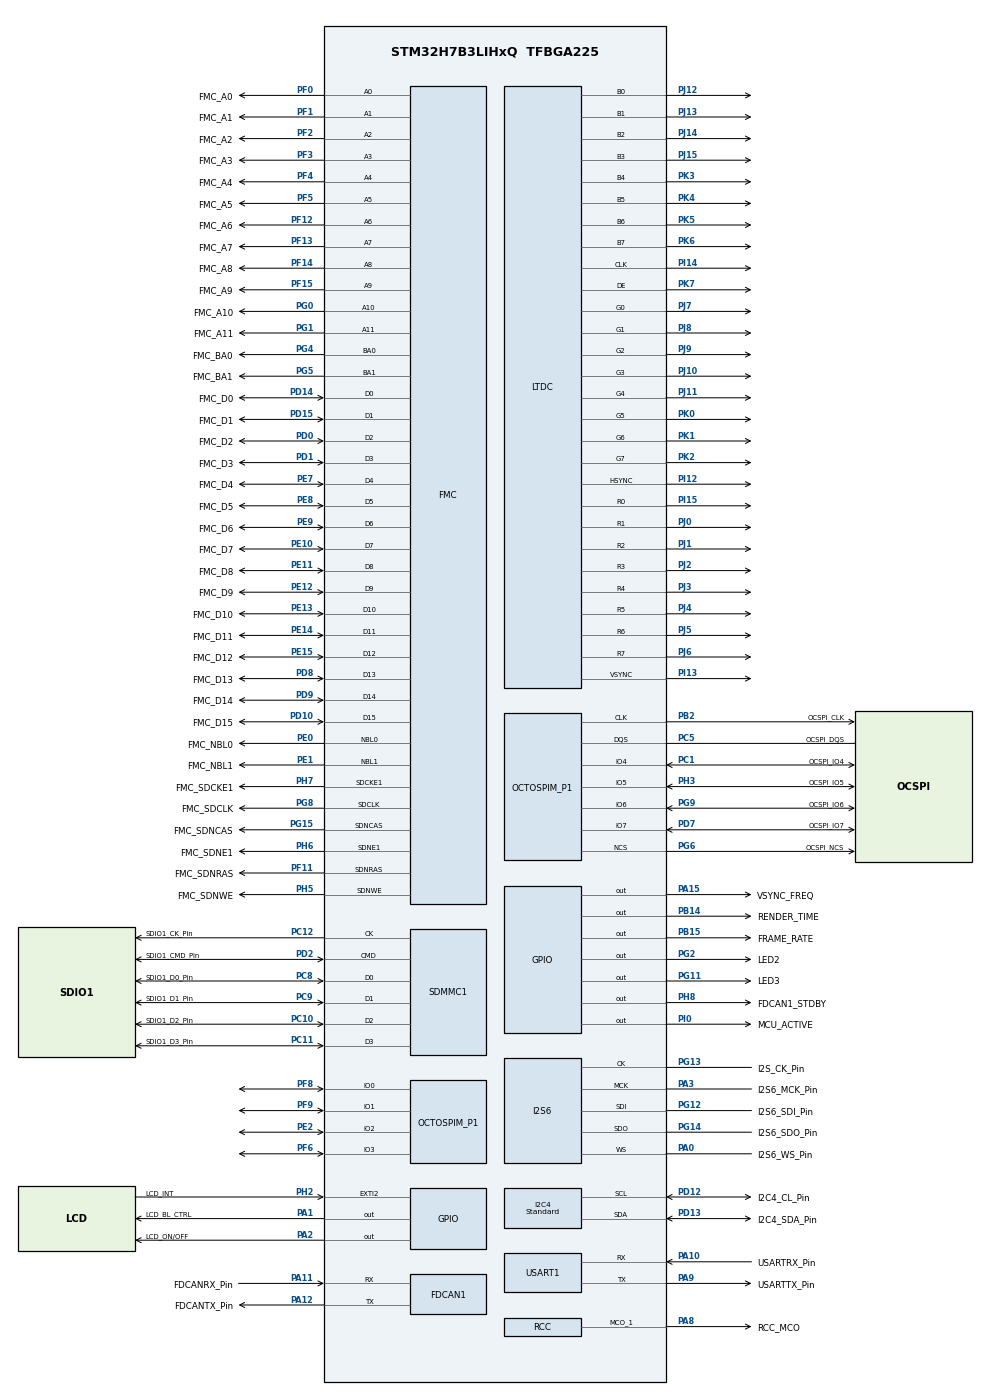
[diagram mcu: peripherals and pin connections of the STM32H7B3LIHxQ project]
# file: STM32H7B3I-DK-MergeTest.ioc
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CORTEX_M7.AccessPermission-Cortex_Memory_Protection_Unit_Region1_Settings=MPU_REGION_FULL_ACCESS
CORTEX_M7.AccessPermission-Cortex_Memory_Protection_Unit_Region2_Settings=MPU_REGION_FULL_ACCESS
CORTEX_M7.AccessPermission-Cortex_Memory_Protection_Unit_Region3_Settings=MPU_REGION_FULL_ACCESS
CORTEX_M7.BaseAddress-Cortex_Memory_Protection_Unit_Region0_Settings=0x90000000
CORTEX_M7.BaseAddress-Cortex_Memory_Protection_Unit_Region1_Settings=0x90000000
CORTEX_M7.BaseAddress-Cortex_Memory_Protection_Unit_Region2_Settings=0x24000000
CORTEX_M7.BaseAddress-Cortex_Memory_Protection_Unit_Region3_Settings=0x24000000
CORTEX_M7.CPU_DCache=Enabled
CORTEX_M7.CPU_ICache=Enabled
CORTEX_M7.DisableExec-Cortex_Memory_Protection_Unit_Region0_Settings=MPU_INSTRUCTION_ACCESS_DISABLE
CORTEX_M7.DisableExec-Cortex_Memory_Protection_Unit_Region1_Settings=MPU_INSTRUCTION_ACCESS_DISABLE
CORTEX_M7.DisableExec-Cortex_Memory_Protection_Unit_Region2_Settings=MPU_INSTRUCTION_ACCESS_DISABLE
CORTEX_M7.DisableExec-Cortex_Memory_Protection_Unit_Region3_Settings=MPU_INSTRUCTION_ACCESS_DISABLE
CORTEX_M7.Enable-Cortex_Memory_Protection_Unit_Region0_Settings=MPU_REGION_ENABLE
CORTEX_M7.Enable-Cortex_Memory_Protection_Unit_Region1_Settings=MPU_REGION_ENABLE
CORTEX_M7.Enable-Cortex_Memory_Protection_Unit_Region2_Settings=MPU_REGION_ENABLE
CORTEX_M7.Enable-Cortex_Memory_Protection_Unit_Region3_Settings=MPU_REGION_ENABLE
CORTEX_M7.IsBufferable-Cortex_Memory_Protection_Unit_Region3_Settings=MPU_ACCESS_BUFFERABLE
CORTEX_M7.IsCacheable-Cortex_Memory_Protection_Unit_Region1_Settings=MPU_ACCESS_CACHEABLE
CORTEX_M7.IsCacheable-Cortex_Memory_Protection_Unit_Region2_Settings=MPU_ACCESS_CACHEABLE
CORTEX_M7.IsCacheable-Cortex_Memory_Protection_Unit_Region3_Settings=MPU_ACCESS_CACHEABLE
CORTEX_M7.MPU_Control=MPU_PRIVILEGED_DEFAULT
CORTEX_M7.Size-Cortex_Memory_Protection_Unit_Region0_Settings=MPU_REGION_SIZE_256MB
CORTEX_M7.Size-Cortex_Memory_Protection_Unit_Region1_Settings=MPU_REGION_SIZE_64MB
CORTEX_M7.Size-Cortex_Memory_Protection_Unit_Region2_Settings=MPU_REGION_SIZE_1MB
CORTEX_M7.Size-Cortex_Memory_Protection_Unit_Region3_Settings=MPU_REGION_SIZE_256KB
DMA2D.ColorMode=DMA2D_OUTPUT_RGB565
Dma.Request0=USART1_TX
Dma.USART1_TX.0.Direction=DMA_MEMORY_TO_PERIPH
Dma.USART1_TX.0.EventEnable=DISABLE
Dma.USART1_TX.0.FIFOMode=DMA_FIFOMODE_DISABLE
Dma.USART1_TX.0.Instance=DMA1_Stream0
Dma.USART1_TX.0.MemDataAlignment=DMA_MDATAALIGN_BYTE
Dma.USART1_TX.0.MemInc=DMA_MINC_ENABLE
Dma.USART1_TX.0.Mode=DMA_NORMAL
Dma.USART1_TX.0.PeriphDataAlignment=DMA_PDATAALIGN_BYTE
Dma.USART1_TX.0.PeriphInc=DMA_PINC_DISABLE
Dma.USART1_TX.0.Polarity=HAL_DMAMUX_REQ_GEN_RISING
Dma.USART1_TX.0.Priority=DMA_PRIORITY_LOW
Dma.USART1_TX.0.RequestNumber=1
Dma.USART1_TX.0.SignalID=NONE
Dma.USART1_TX.0.SyncEnable=DISABLE
Dma.USART1_TX.0.SyncPolarity=HAL_DMAMUX_SYNC_NO_EVENT
Dma.USART1_TX.0.SyncRequestNumber=1
Dma.USART1_TX.0.SyncSignalID=NONE
FDCAN1.NominalSyncJumpWidth=8
FDCAN1.NominalTimeSeg1=31
FDCAN1.NominalTimeSeg2=8
FDCAN1.ProtocolException=ENABLE
FDCAN1.RxFifo0ElmtsNbr=64
FDCAN1.RxFifo1ElmtsNbr=64
FDCAN1.StdFiltersNbr=16
FMC.ColumnBitsNumber1=FMC_SDRAM_COLUMN_BITS_NUM_9
FMC.ExitSelfRefreshDelay1=7
FMC.LoadToActiveDelay1=2
FMC.RCDDelay1=2
FMC.RPDelay1=2
FMC.RPDelay2=2
FMC.ReadBurst1=FMC_SDRAM_RBURST_ENABLE
FMC.ReadBurst2=FMC_SDRAM_RBURST_ENABLE
FMC.ReadPipeDelay1=FMC_SDRAM_RPIPE_DELAY_2
FMC.ReadPipeDelay2=FMC_SDRAM_RPIPE_DELAY_2
FMC.RowCycleDelay1=7
FMC.RowCycleDelay2=7
FMC.SDClockPeriod1=FMC_SDRAM_CLOCK_PERIOD_3
FMC.SDClockPeriod2=FMC_SDRAM_CLOCK_PERIOD_3
FMC.SelfRefreshTime1=4
FMC.WriteRecoveryTime1=4
FREERTOS.Tasks01=defaultTask,0,128,StartDefaultTask,Default,NULL,Dynamic,NULL,NULL
FREERTOS.configCHECK_FOR_STACK_OVERFLOW=1
FREERTOS.configGENERATE_RUN_TIME_STATS=1
FREERTOS.configRECORD_STACK_HIGH_ADDRESS=1
FREERTOS.configUSE_STATS_FORMATTING_FUNCTIONS=1
FREERTOS.configUSE_TRACE_FACILITY=1
I2C4.I2C_Fall_Time=0
I2C4.I2C_Rise_Time=0
I2C4.I2C_Speed_Mode=I2C_Standard
I2C4.Speed=100
I2C4.Timeout=0x000085B8
I2C4.Timing=0x307075B1
I2S6.FullDuplexMode=I2S_MODE_MASTER_FD
I2S6.Instance=SPI$Index
I2S6.VirtualMode=I2S_MODE_MASTER
LTDC.ActiveH=272
LTDC.ActiveW=480
LTDC.Alpha_L0=255
LTDC.BlendingFactor1_L0=LTDC_BLENDING_FACTOR1_CA
LTDC.BlendingFactor2_L0=LTDC_BLENDING_FACTOR2_CA
LTDC.Blue_L0=255
LTDC.FBStartAdress_L0=0x90000000
LTDC.HBP=2
LTDC.HFP=32
LTDC.HSync=41
LTDC.ImageHeight_L0=272
LTDC.ImageWidth_L0=480
LTDC.Layers=0
LTDC.PixelFormat_L0=LTDC_PIXEL_FORMAT_RGB888
LTDC.VSync=10
LTDC.WindowX1_L0=480
LTDC.WindowY1_L0=272
Mcu.Family=STM32H7
Mcu.Name=STM32H7B3LIHxQ
Mcu.Package=TFBGA225
NVIC.DMA1_Stream0_IRQn=true\:0\:0\:false\:false\:true\:true\:false\:true
NVIC.DMA2D_IRQn=true\:5\:0\:true\:false\:true\:true\:true\:true
NVIC.EXTI2_IRQn=true\:5\:0\:false\:false\:true\:true\:true\:true
NVIC.FDCAN1_IT0_IRQn=true\:5\:0\:true\:false\:true\:true\:true\:true
NVIC.FDCAN1_IT1_IRQn=true\:5\:0\:true\:false\:true\:true\:true\:true
NVIC.LTDC_IRQn=true\:5\:0\:false\:false\:true\:true\:true\:true
NVIC.PriorityGroup=NVIC_PRIORITYGROUP_4
NVIC.TIM7_IRQn=true\:0\:0\:false\:false\:true\:false\:false\:true
NVIC.TimeBase=TIM7_IRQn
NVIC.TimeBaseIP=TIM7
NVIC.USART1_IRQn=true\:5\:0\:true\:false\:true\:true\:true\:true
OCTOSPI1.ChipSelectBoundary=1
OCTOSPI1.ChipSelectHighTime=2
OCTOSPI1.ClockPrescaler=1
OCTOSPI1.DelayHoldQuarterCycle=HAL_OSPI_DHQC_ENABLE
OCTOSPI1.DeviceSize=26
OCTOSPI1.MemoryType=HAL_OSPI_MEMTYPE_MACRONIX
OCTOSPI1.Refresh=0
PA0.GPIO_Label=I2S6_WS_Pin
PA0.Mode=Full_Duplex_Master
PA0.Signal=I2S6_WS
PA1.GPIO_Label=LCD_BL_CTRL
PA1.GPIO_ModeDefaultOutputPP=GPIO_MODE_OUTPUT_PP
PA1.GPIO_PuPd=GPIO_NOPULL
PA1.GPIO_Speed=GPIO_SPEED_FREQ_LOW
PA1.PinState=GPIO_PIN_RESET
PA1.Signal=GPIO_Output
PA10.GPIO_Label=USARTRX_Pin
PA10.Mode=Asynchronous
PA10.Signal=USART1_RX
PA11.GPIO_Label=FDCANRX_Pin
PA11.Mode=FDCANMaster
PA11.Signal=FDCAN1_RX
PA12.GPIO_Label=FDCANTX_Pin
PA12.Mode=FDCANMaster
PA12.Signal=FDCAN1_TX
PA15.GPIO_Label=VSYNC_FREQ
PA15.Signal=GPIO_Output
PA2.GPIO_Label=LCD_ON/OFF
PA2.GPIO_ModeDefaultOutputPP=GPIO_MODE_OUTPUT_PP
PA2.GPIO_PuPd=GPIO_PULLUP
PA2.GPIO_Speed=GPIO_SPEED_FREQ_LOW
PA2.PinState=GPIO_PIN_RESET
PA2.Signal=GPIO_Output
PA3.GPIO_Label=I2S6_MCK_Pin
PA3.Mode=Master_Clock_Activated
PA3.Signal=I2S6_MCK
PA8.GPIO_Label=RCC_MCO
PA8.Mode=Clock-out-1
PA8.Signal=RCC_MCO_1
PA9.GPIO_Label=USARTTX_Pin
PA9.Mode=Asynchronous
PA9.Signal=USART1_TX
PB14.GPIO_Label=RENDER_TIME
PB14.Signal=GPIO_Output
PB15.GPIO_Label=FRAME_RATE
PB15.Signal=GPIO_Output
PB2.GPIO_Label=OCSPI_CLK
PB2.Mode=OCTOSPI1_Port1_CLK
PB2.Signal=OCTOSPIM_P1_CLK
PC1.GPIO_Label=OCSPI_IO4
PC1.Mode=OCTOSPI1_IOH_Port1H
PC1.Signal=OCTOSPIM_P1_IO4
PC10.GPIO_Label=SDIO1_D2_Pin
PC10.Mode=SD_4_bits_Wide_bus
PC10.Signal=SDMMC1_D2
PC11.GPIO_Label=SDIO1_D3_Pin
PC11.Mode=SD_4_bits_Wide_bus
PC11.Signal=SDMMC1_D3
PC12.GPIO_Label=SDIO1_CK_Pin
PC12.Mode=SD_4_bits_Wide_bus
PC12.Signal=SDMMC1_CK
PC14-OSC32_IN.GPIO_Label=RCC_OSC32_IN
PC14-OSC32_IN.Mode=LSE-External-Oscillator
PC14-OSC32_IN.Signal=RCC_OSC32_IN
PC15-OSC32_OUT.GPIO_Label=RCC_OSC32_OUT
PC15-OSC32_OUT.Mode=LSE-External-Oscillator
PC15-OSC32_OUT.Signal=RCC_OSC32_OUT
PC5.GPIO_Label=OCSPI_DQS
PC5.Mode=OCTOSPI1_Port1_DQS
PC5.Signal=OCTOSPIM_P1_DQS
PC8.GPIO_Label=SDIO1_D0_Pin
PC8.Mode=SD_4_bits_Wide_bus
PC8.Signal=SDMMC1_D0
PC9.GPIO_Label=SDIO1_D1_Pin
PC9.Mode=SD_4_bits_Wide_bus
PC9.Signal=SDMMC1_D1
PD0.GPIO_Label=FMC_D2
PD0.Signal=FMC_D2_DA2
PD1.GPIO_Label=FMC_D3
PD1.Signal=FMC_D3_DA3
PD10.GPIO_Label=FMC_D15
PD10.Signal=FMC_D15_DA15
PD12.GPIO_Label=I2C4_CL_Pin
PD12.GPIO_Speed=GPIO_SPEED_FREQ_LOW
PD12.Mode=I2C
PD12.Signal=I2C4_SCL
PD13.GPIO_Label=I2C4_SDA_Pin
PD13.GPIO_Speed=GPIO_SPEED_FREQ_LOW
PD13.Mode=I2C
PD13.Signal=I2C4_SDA
PD14.GPIO_Label=FMC_D0
PD14.Signal=FMC_D0_DA0
PD15.GPIO_Label=FMC_D1
PD15.Signal=FMC_D1_DA1
PD2.GPIO_Label=SDIO1_CMD_Pin
PD2.Mode=SD_4_bits_Wide_bus
PD2.Signal=SDMMC1_CMD
PD7.GPIO_Label=OCSPI_IO7
PD7.Mode=OCTOSPI1_IOH_Port1H
PD7.Signal=OCTOSPIM_P1_IO7
PD8.GPIO_Label=FMC_D13
PD8.Signal=FMC_D13_DA13
PD9.GPIO_Label=FMC_D14
PD9.Signal=FMC_D14_DA14
PE0.GPIO_Label=FMC_NBL0
PE0.Signal=FMC_NBL0
PE1.GPIO_Label=FMC_NBL1
PE1.Signal=FMC_NBL1
PE10.GPIO_Label=FMC_D7
PE10.Signal=FMC_D7_DA7
PE11.GPIO_Label=FMC_D8
PE11.Signal=FMC_D8_DA8
PE12.GPIO_Label=FMC_D9
PE12.Signal=FMC_D9_DA9
PE13.GPIO_Label=FMC_D10
PE13.Signal=FMC_D10_DA10
PE14.GPIO_Label=FMC_D11
PE14.Signal=FMC_D11_DA11
PE15.GPIO_Label=FMC_D12
PE15.Signal=FMC_D12_DA12
PE2.Mode=OCTOSPI1_IOL_Port1L2
PE2.Signal=OCTOSPIM_P1_IO2
PE7.GPIO_Label=FMC_D4
PE7.Signal=FMC_D4_DA4
PE8.GPIO_Label=FMC_D5
PE8.Signal=FMC_D5_DA5
PE9.GPIO_Label=FMC_D6
PE9.Signal=FMC_D6_DA6
PF0.GPIO_Label=FMC_A0
PF0.Signal=FMC_A0
PF1.GPIO_Label=FMC_A1
PF1.Signal=FMC_A1
PF11.GPIO_Label=FMC_SDNRAS
PF11.Signal=FMC_SDNRAS
PF12.GPIO_Label=FMC_A6
PF12.Signal=FMC_A6
PF13.GPIO_Label=FMC_A7
PF13.Signal=FMC_A7
PF14.GPIO_Label=FMC_A8
PF14.Signal=FMC_A8
PF15.GPIO_Label=FMC_A9
PF15.Signal=FMC_A9
PF2.GPIO_Label=FMC_A2
PF2.Signal=FMC_A2
PF3.GPIO_Label=FMC_A3
PF3.Signal=FMC_A3
PF4.GPIO_Label=FMC_A4
PF4.Signal=FMC_A4
PF5.GPIO_Label=FMC_A5
PF5.Signal=FMC_A5
PF6.Mode=OCTOSPI1_IOL_Port1L2
PF6.Signal=OCTOSPIM_P1_IO3
PF8.Mode=OCTOSPI1_IOL_Port1L2
PF8.Signal=OCTOSPIM_P1_IO0
PF9.Mode=OCTOSPI1_IOL_Port1L2
PF9.Signal=OCTOSPIM_P1_IO1
PG0.GPIO_Label=FMC_A10
PG0.Signal=FMC_A10
PG1.GPIO_Label=FMC_A11
PG1.Signal=FMC_A11
PG11.GPIO_Label=LED3
PG11.Signal=GPIO_Output
PG12.GPIO_Label=I2S6_SDI_Pin
PG12.Mode=Full_Duplex_Master
PG12.Signal=I2S6_SDI
PG13.GPIO_Label=I2S_CK_Pin
PG13.Mode=Full_Duplex_Master
PG13.Signal=I2S6_CK
PG14.GPIO_Label=I2S6_SDO_Pin
PG14.Mode=Full_Duplex_Master
PG14.Signal=I2S6_SDO
PG15.GPIO_Label=FMC_SDNCAS
PG15.Signal=FMC_SDNCAS
PG2.GPIO_Label=LED2
PG2.Signal=GPIO_Output
PG4.GPIO_Label=FMC_BA0
PG4.Signal=FMC_A14_BA0
PG5.GPIO_Label=FMC_BA1
PG5.Signal=FMC_A15_BA1
PG6.GPIO_Label=OCSPI_NCS
PG6.Mode=OCTOSPI1_Port1_NCS
PG6.Signal=OCTOSPIM_P1_NCS
PG8.GPIO_Label=FMC_SDCLK
PG8.Signal=FMC_SDCLK
PG9.GPIO_Label=OCSPI_IO6
PG9.Mode=OCTOSPI1_IOH_Port1H
PG9.Signal=OCTOSPIM_P1_IO6
PH0-OSC_IN.GPIO_Label=RCC_OSC_IN
PH0-OSC_IN.Mode=HSE-External-Oscillator
PH0-OSC_IN.Signal=RCC_OSC_IN
PH1-OSC_OUT.GPIO_Label=RCC_OSC_OUT
PH1-OSC_OUT.Mode=HSE-External-Oscillator
PH1-OSC_OUT.Signal=RCC_OSC_OUT
PH2.GPIO_Label=LCD_INT
PH2.GPIO_PuPd=GPIO_PULLUP
PH2.Signal=GPXTI2
PH3.GPIO_Label=OCSPI_IO5
PH3.Mode=OCTOSPI1_IOH_Port1H
PH3.Signal=OCTOSPIM_P1_IO5
PH5.GPIO_Label=FMC_SDNWE
PH5.Signal=FMC_SDNWE
PH6.GPIO_Label=FMC_SDNE1
PH6.Mode=SdramChipSelect2_1
PH6.Signal=FMC_SDNE1
PH7.GPIO_Label=FMC_SDCKE1
PH7.Mode=SdramChipSelect2_1
PH7.Signal=FMC_SDCKE1
PH8.GPIO_Label=FDCAN1_STDBY
PH8.Signal=GPIO_Output
PI0.GPIO_Label=MCU_ACTIVE
PI0.Signal=GPIO_Output
PI12.Mode=RGB888
PI12.Signal=LTDC_HSYNC
PI13.Mode=RGB888
PI13.Signal=LTDC_VSYNC
PI14.Mode=RGB888
PI14.Signal=LTDC_CLK
PI15.Mode=RGB888
PI15.Signal=LTDC_R0
PJ0.Mode=RGB888
PJ0.Signal=LTDC_R1
PJ1.Mode=RGB888
PJ1.Signal=LTDC_R2
PJ10.Mode=RGB888
PJ10.Signal=LTDC_G3
PJ11.Mode=RGB888
PJ11.Signal=LTDC_G4
PJ12.Mode=RGB888
PJ12.Signal=LTDC_B0
PJ13.Mode=RGB888
PJ13.Signal=LTDC_B1
PJ14.Mode=RGB888
PJ14.Signal=LTDC_B2
PJ15.Mode=RGB888
PJ15.Signal=LTDC_B3
PJ2.Mode=RGB888
PJ2.Signal=LTDC_R3
PJ3.Mode=RGB888
PJ3.Signal=LTDC_R4
PJ4.Mode=RGB888
PJ4.Signal=LTDC_R5
PJ5.Mode=RGB888
PJ5.Signal=LTDC_R6
PJ6.Mode=RGB888
PJ6.Signal=LTDC_R7
PJ7.Mode=RGB888
PJ7.Signal=LTDC_G0
PJ8.Mode=RGB888
PJ8.Signal=LTDC_G1
PJ9.Mode=RGB888
PJ9.Signal=LTDC_G2
PK0.Mode=RGB888
PK0.Signal=LTDC_G5
PK1.Mode=RGB888
PK1.Signal=LTDC_G6
PK2.Mode=RGB888
PK2.Signal=LTDC_G7
PK3.Mode=RGB888
PK3.Signal=LTDC_B4
PK4.Mode=RGB888
PK4.Signal=LTDC_B5
PK5.Mode=RGB888
PK5.Signal=LTDC_B6
PK6.Mode=RGB888
PK6.Signal=LTDC_B7
PK7.GPIO_PuPd=GPIO_NOPULL
PK7.Mode=RGB888
PK7.Signal=LTDC_DE
ProjectManager.HeapSize=0x1000
ProjectManager.StackSize=0x1000
ProjectManager.TargetToolchain=STM32CubeIDE
RCC.ADCFreq_Value=64000488.28125
RCC.APB1Freq_Value=120000000
RCC.APB2Freq_Value=120000000
RCC.APB3Freq_Value=120000000
RCC.APB4Freq_Value=120000000
RCC.CortexFreq_Value=120000000
RCC.DIVM1=2
RCC.DIVM2=2
RCC.DIVM3=2
RCC.DIVN1=20
RCC.DIVN2=10
RCC.DIVN3=12
RCC.DIVQ1=12
RCC.DIVR2=1
RCC.DIVR3=15
RCC.HCLKFreq_Value=120000000
RCC.PLL2FRACN=5462
RCC.PLL3FRACN=4096
RCC.PLLFRACN=0
RCC.PLLSourceVirtual=RCC_PLLSOURCE_HSE
RCC.QSPICLockSelection=RCC_OSPICLKSOURCE_PLL2
RCC.RCC_MCO1Source=RCC_MCO1SOURCE_HSE
RCC.RTCClockSelection=RCC_RTCCLKSOURCE_LSE
RCC.SDMMC1CLockSelection=RCC_SDMMCCLKSOURCE_PLL2
RCC.SYSCLKFreq_VALUE=120000000
RCC.SYSCLKSource=RCC_SYSCLKSOURCE_PLLCLK
RCC.SupplySource=PWR_DIRECT_SMPS_SUPPLY
RCC.USBFreq_Value=20000000
SH.FMC_A0.0=FMC_A0,12b-sda1
SH.FMC_A1.0=FMC_A1,12b-sda1
SH.FMC_A10.0=FMC_A10,12b-sda1
SH.FMC_A11.0=FMC_A11,12b-sda1
SH.FMC_A14_BA0.0=FMC_BA0,FourSdramBanks1
SH.FMC_A15_BA1.0=FMC_BA1,FourSdramBanks1
SH.FMC_A2.0=FMC_A2,12b-sda1
SH.FMC_A3.0=FMC_A3,12b-sda1
SH.FMC_A4.0=FMC_A4,12b-sda1
SH.FMC_A5.0=FMC_A5,12b-sda1
SH.FMC_A6.0=FMC_A6,12b-sda1
SH.FMC_A7.0=FMC_A7,12b-sda1
SH.FMC_A8.0=FMC_A8,12b-sda1
SH.FMC_A9.0=FMC_A9,12b-sda1
SH.FMC_D0_DA0.0=FMC_D0,sd-16b-d1
SH.FMC_D10_DA10.0=FMC_D10,sd-16b-d1
SH.FMC_D11_DA11.0=FMC_D11,sd-16b-d1
SH.FMC_D12_DA12.0=FMC_D12,sd-16b-d1
SH.FMC_D13_DA13.0=FMC_D13,sd-16b-d1
SH.FMC_D14_DA14.0=FMC_D14,sd-16b-d1
SH.FMC_D15_DA15.0=FMC_D15,sd-16b-d1
SH.FMC_D1_DA1.0=FMC_D1,sd-16b-d1
SH.FMC_D2_DA2.0=FMC_D2,sd-16b-d1
SH.FMC_D3_DA3.0=FMC_D3,sd-16b-d1
SH.FMC_D4_DA4.0=FMC_D4,sd-16b-d1
SH.FMC_D5_DA5.0=FMC_D5,sd-16b-d1
SH.FMC_D6_DA6.0=FMC_D6,sd-16b-d1
SH.FMC_D7_DA7.0=FMC_D7,sd-16b-d1
SH.FMC_D8_DA8.0=FMC_D8,sd-16b-d1
SH.FMC_D9_DA9.0=FMC_D9,sd-16b-d1
SH.FMC_NBL0.0=FMC_NBL0,Sd2ByteEnable1
SH.FMC_NBL1.0=FMC_NBL1,Sd2ByteEnable1
SH.FMC_SDCLK.0=FMC_SDCLK,12b-sda1
SH.FMC_SDNCAS.0=FMC_SDNCAS,12b-sda1
SH.FMC_SDNRAS.0=FMC_SDNRAS,12b-sda1
SH.FMC_SDNWE.0=FMC_SDNWE,12b-sda1
STMicroelectronics.X-CUBE-TOUCHGFX.4.14.0.ApplicationCcGraphicsJjApplication=TouchGFXOoGenerator
STMicroelectronics.X-CUBE-TOUCHGFX.4.14.0.tgfx_address1=0x24040000
STMicroelectronics.X-CUBE-TOUCHGFX.4.14.0.tgfx_address2=0x2409FA00
STMicroelectronics.X-CUBE-TOUCHGFX.4.14.0.tgfx_buffering_strategy=Double
STMicroelectronics.X-CUBE-TOUCHGFX.4.14.0.tgfx_display_interface=disp_ltdc
STMicroelectronics.X-CUBE-TOUCHGFX.4.14.0.tgfx_hardware_accelerator=dma_2d
STMicroelectronics.X-CUBE-TOUCHGFX.4.14.0.tgfx_location=Allocate
STMicroelectronics.X-CUBE-TOUCHGFX.4.14.0.tgfx_pixel_format=RGB888\:24
STMicroelectronics.X-CUBE-TOUCHGFX.4.14.0.tgfx_vsync=vsync_ltdc
USART1.DMADisableonRxErrorParam=ADVFEATURE_DMA_ENABLEONRXERROR
USART1.OverrunDisableParam=ADVFEATURE_OVERRUN_ENABLE
USART1.VirtualMode-Asynchronous=VM_ASYNC
VP_CRC_VS_CRC.Mode=CRC_Activate
VP_DMA2D_VS_DMA2D.Mode=DMA2D_Activate
VP_FREERTOS_VS_CMSIS_V1.Mode=CMSIS_V1
VP_OCTOSPI1_VS_octo.Mode=octo_mode
VP_RTC_VS_RTC_Activate.Mode=RTC_Enabled
VP_STMicroelectronics.X-CUBE-TOUCHGFX_VS_GraphicsJjApplication_4.14.0.Mode=GraphicsJjApplication
VP_SYS_VS_tim7.Mode=TIM7
board=custom

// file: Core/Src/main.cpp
/*
 * main.cpp
 *
 *  Created on: 8. nov. 2020
 *      Author: mohasa18
 */

/* USER CODE BEGIN Header */
/**
  ******************************************************************************
  * @file           : main.c
  * @brief          : Main program body
  ******************************************************************************
  * @attention
  *
  * <h2><center>&copy; Copyright (c) 2020 STMicroelectronics.
  * All rights reserved.</center></h2>
  *
  * This software component is licensed by ST under Ultimate Liberty license
  * SLA0044, the "License"; You may not use this file except in compliance with
  * the License. You may obtain a copy of the License at:
  *                             www.st.com/SLA0044
  *
  ******************************************************************************
  */
/* USER CODE END Header */

#include <CANClass.hpp>
#include "main.h"
#include "cmsis_os.h"
#include "app_touchgfx.h"
#include <iostream>
#include "timer.hpp"
/* USER CODE BEGIN Includes */
#include <stdarg.h>
#include <stdio.h>
#include <stdint.h>
#include <string.h>
#include "Brightness.hpp"
#include "stm32h7b3i_discovery_sdram.h"
#include "stm32h7b3i_discovery_ospi.h"
/* USER CODE END Includes */

CRC_HandleTypeDef hcrc;

DMA2D_HandleTypeDef hdma2d;

FDCAN_HandleTypeDef hfdcan1;

I2C_HandleTypeDef hi2c4;

I2S_HandleTypeDef hi2s6;

LTDC_HandleTypeDef hltdc;

OSPI_HandleTypeDef hospi1;

RTC_HandleTypeDef hrtc;

SD_HandleTypeDef hsd1;

UART_HandleTypeDef huart1;
DMA_HandleTypeDef hdma_usart1_tx;

osThreadId GUI_TaskHandle;

/* USER CODE BEGIN PV */

FDCAN_FilterTypeDef sFilterConfig;
/* Status variables */

/* Counter index */
uint32_t time_seconds = 0;

uint32_t SDRAM_instance = 0;

/* USER CODE END PV */

void SystemClock_Config(void);
static void MPU_Config(void);
static void MX_DMA_Init(void);
static void MX_GPIO_Init(void);
static void MX_DMA2D_Init(void);
static void MX_LTDC_Init(void);
static void MX_I2C4_Init(void);
static void MX_OCTOSPI1_Init(void);
static void MX_FDCAN1_Init(void);
static void MX_USART1_UART_Init(void);
static void MX_CRC_Init(void);
static void MX_I2S6_Init(void);
static void MX_SDMMC1_SD_Init(void);
static void MX_RTC_Init(void);

extern "C" void TouchGFX_Task(void const * argument);

/* USER CODE BEGIN PFP */
extern "C" void MX_TouchGFX_Init(void);
extern "C" void MX_TouchGFX_Process(void);
extern "C" int32_t BSP_SDRAM_Init(uint32_t Instance);
extern void AppCanInit(FDCAN_HandleTypeDef *hfdcan);
void Printf(const char *fmt, ...);
/* USER CODE END PFP */

/* USER CODE BEGIN 0 */
CAN can;

/* USER CODE END 0 */

int main(void)
{

  /* MPU Configuration--------------------------------------------------------*/
  MPU_Config();

  /* Enable I-Cache---------------------------------------------------------*/
  SCB_EnableICache();

  /* Enable D-Cache---------------------------------------------------------*/
  SCB_EnableDCache();

  /* MCU Configuration--------------------------------------------------------*/

  /* Reset of all peripherals, Initializes the Flash interface and the Systick. */
  HAL_Init();

  /* Configure the system clock */
  SystemClock_Config();

  /* Initialize all configured peripherals */
  MX_DMA_Init();
  MX_GPIO_Init();
  MX_DMA2D_Init();
  MX_LTDC_Init();
  MX_I2C4_Init();
  MX_OCTOSPI1_Init();
  MX_FDCAN1_Init();
  MX_USART1_UART_Init();
  MX_CRC_Init();
  MX_I2S6_Init();
  MX_SDMMC1_SD_Init();
  MX_RTC_Init();

  MX_TouchGFX_Init();
  /* USER CODE BEGIN 2 */
//  RTC_DateTypeDef sdatestructureget;
//  RTC_TimeTypeDef stimestructureget;
//
//  /* Get the RTC current Time */
//  HAL_RTC_GetTime(&hrtc, &stimestructureget, RTC_FORMAT_BIN);
//  /* Get the RTC current Date */
//  HAL_RTC_GetDate(&hrtc, &sdatestructureget, RTC_FORMAT_BIN);

  /* USER CODE END 2 */
  /* Init scheduler */

  /* Create the thread(s) */

  /* USER CODE BEGIN RTOS_THREADS */
  /* add threads, ... */
  BSP_SDRAM_Init( SDRAM_instance);
  /* Program the SDRAM external device */

  Printf("calling AppCanInit!\r\n");
  AppCanInit(&hfdcan1);
  Printf("calling App_timer_Init!\r\n");
//  App_timer_init();
  /* creation of GUI_Task */
  osThreadDef(GUI_Task, TouchGFX_Task, osPriorityNormal, 1, 2096);
  GUI_TaskHandle = osThreadCreate(osThread(GUI_Task), NULL);

  brightnessInit();

  /* USER CODE END RTOS_THREADS */

  /* Start scheduler */
  osKernelStart();

  /* We should never get here as control is now taken by the scheduler */

  /* Infinite loop */
  while (1)
  {

  }
}

void SystemClock_Config(void)
{
  RCC_OscInitTypeDef RCC_OscInitStruct = {0};
  RCC_ClkInitTypeDef RCC_ClkInitStruct = {0};
  RCC_PeriphCLKInitTypeDef PeriphClkInitStruct = {0};

  /** Supply configuration update enable
  */
  HAL_PWREx_ConfigSupply(PWR_DIRECT_SMPS_SUPPLY);
  /** Configure the main internal regulator output voltage
  */
  __HAL_PWR_VOLTAGESCALING_CONFIG(PWR_REGULATOR_VOLTAGE_SCALE2);

  while(!__HAL_PWR_GET_FLAG(PWR_FLAG_VOSRDY)) {}
  /** Configure LSE Drive Capability
  */
  HAL_PWR_EnableBkUpAccess();
  __HAL_RCC_LSEDRIVE_CONFIG(RCC_LSEDRIVE_LOW);
  /** Macro to configure the PLL clock source
  */
  __HAL_RCC_PLL_PLLSOURCE_CONFIG(RCC_PLLSOURCE_HSE);
  /** Initializes the CPU, AHB and APB busses clocks
  */
  RCC_OscInitStruct.OscillatorType = RCC_OSCILLATORTYPE_HSE|RCC_OSCILLATORTYPE_LSE;
  RCC_OscInitStruct.HSEState = RCC_HSE_ON;
  RCC_OscInitStruct.LSEState = RCC_LSE_ON;
  RCC_OscInitStruct.PLL.PLLState = RCC_PLL_ON;
  RCC_OscInitStruct.PLL.PLLSource = RCC_PLLSOURCE_HSE;
  RCC_OscInitStruct.PLL.PLLM = 2;
  RCC_OscInitStruct.PLL.PLLN = 20;
  RCC_OscInitStruct.PLL.PLLP = 2;
  RCC_OscInitStruct.PLL.PLLQ = 12;
  RCC_OscInitStruct.PLL.PLLR = 2;
  RCC_OscInitStruct.PLL.PLLRGE = RCC_PLL1VCIRANGE_3;
  RCC_OscInitStruct.PLL.PLLVCOSEL = RCC_PLL1VCOWIDE;
  RCC_OscInitStruct.PLL.PLLFRACN = 0;
  if (HAL_RCC_OscConfig(&RCC_OscInitStruct) != HAL_OK)
  {
    Error_Handler();
  }
  /** Initializes the CPU, AHB and APB busses clocks
  */
  RCC_ClkInitStruct.ClockType = RCC_CLOCKTYPE_HCLK|RCC_CLOCKTYPE_SYSCLK
                              |RCC_CLOCKTYPE_PCLK1|RCC_CLOCKTYPE_PCLK2
                              |RCC_CLOCKTYPE_D3PCLK1|RCC_CLOCKTYPE_D1PCLK1;
  RCC_ClkInitStruct.SYSCLKSource = RCC_SYSCLKSOURCE_PLLCLK;
  RCC_ClkInitStruct.SYSCLKDivider = RCC_SYSCLK_DIV1;
  RCC_ClkInitStruct.AHBCLKDivider = RCC_HCLK_DIV1;
  RCC_ClkInitStruct.APB3CLKDivider = RCC_APB3_DIV1;
  RCC_ClkInitStruct.APB1CLKDivider = RCC_APB1_DIV1;
  RCC_ClkInitStruct.APB2CLKDivider = RCC_APB2_DIV1;
  RCC_ClkInitStruct.APB4CLKDivider = RCC_APB4_DIV1;

  if (HAL_RCC_ClockConfig(&RCC_ClkInitStruct, FLASH_LATENCY_2) != HAL_OK)
  {
    Error_Handler();
  }
  PeriphClkInitStruct.PeriphClockSelection = RCC_PERIPHCLK_RTC|RCC_PERIPHCLK_LTDC
                              |RCC_PERIPHCLK_FDCAN|RCC_PERIPHCLK_USART16
                              |RCC_PERIPHCLK_SDMMC|RCC_PERIPHCLK_I2C4
                              |RCC_PERIPHCLK_OSPI|RCC_PERIPHCLK_FMC;
  PeriphClkInitStruct.PLL2.PLL2M = 2;
  PeriphClkInitStruct.PLL2.PLL2N = 10;
  PeriphClkInitStruct.PLL2.PLL2P = 2;
  PeriphClkInitStruct.PLL2.PLL2Q = 2;
  PeriphClkInitStruct.PLL2.PLL2R = 1;
  PeriphClkInitStruct.PLL2.PLL2RGE = RCC_PLL2VCIRANGE_3;
  PeriphClkInitStruct.PLL2.PLL2VCOSEL = RCC_PLL2VCOWIDE;
  PeriphClkInitStruct.PLL2.PLL2FRACN = 5462;
  PeriphClkInitStruct.PLL3.PLL3M = 2;
  PeriphClkInitStruct.PLL3.PLL3N = 12;
  PeriphClkInitStruct.PLL3.PLL3P = 2;
  PeriphClkInitStruct.PLL3.PLL3Q = 2;
  PeriphClkInitStruct.PLL3.PLL3R = 15;
  PeriphClkInitStruct.PLL3.PLL3RGE = RCC_PLL3VCIRANGE_3;
  PeriphClkInitStruct.PLL3.PLL3VCOSEL = RCC_PLL3VCOWIDE;
  PeriphClkInitStruct.PLL3.PLL3FRACN = 4096;
  PeriphClkInitStruct.FmcClockSelection = RCC_FMCCLKSOURCE_D1HCLK;
  PeriphClkInitStruct.OspiClockSelection = RCC_OSPICLKSOURCE_PLL2;
  PeriphClkInitStruct.SdmmcClockSelection = RCC_SDMMCCLKSOURCE_PLL2;
  PeriphClkInitStruct.FdcanClockSelection = RCC_FDCANCLKSOURCE_PLL;
  PeriphClkInitStruct.Usart16ClockSelection = RCC_USART16910CLKSOURCE_D2PCLK2;
  PeriphClkInitStruct.I2c4ClockSelection = RCC_I2C4CLKSOURCE_D3PCLK1;
  PeriphClkInitStruct.RTCClockSelection = RCC_RTCCLKSOURCE_LSE;
  if (HAL_RCCEx_PeriphCLKConfig(&PeriphClkInitStruct) != HAL_OK)
  {
    Error_Handler();
  }
  HAL_RCC_MCOConfig(RCC_MCO1, RCC_MCO1SOURCE_HSE, RCC_MCODIV_1);
}

static void MX_CRC_Init(void)
{

  hcrc.Instance = CRC;
  hcrc.Init.DefaultPolynomialUse = DEFAULT_POLYNOMIAL_ENABLE;
  hcrc.Init.DefaultInitValueUse = DEFAULT_INIT_VALUE_ENABLE;
  hcrc.Init.InputDataInversionMode = CRC_INPUTDATA_INVERSION_NONE;
  hcrc.Init.OutputDataInversionMode = CRC_OUTPUTDATA_INVERSION_DISABLE;
  hcrc.InputDataFormat = CRC_INPUTDATA_FORMAT_BYTES;
  if (HAL_CRC_Init(&hcrc) != HAL_OK)
  {
    Error_Handler();
  }

}

static void MX_DMA2D_Init(void)
{

  hdma2d.Instance = DMA2D;
  hdma2d.Init.Mode = DMA2D_M2M;
  hdma2d.Init.ColorMode = DMA2D_OUTPUT_RGB565;
  hdma2d.Init.OutputOffset = 0;
  hdma2d.Init.BytesSwap = DMA2D_BYTES_REGULAR;
  hdma2d.Init.LineOffsetMode = DMA2D_LOM_PIXELS;
  hdma2d.LayerCfg[1].InputOffset = 0;
  hdma2d.LayerCfg[1].InputColorMode = DMA2D_INPUT_RGB565;
  hdma2d.LayerCfg[1].AlphaMode = DMA2D_NO_MODIF_ALPHA;
  hdma2d.LayerCfg[1].InputAlpha = 0;
  hdma2d.LayerCfg[1].AlphaInverted = DMA2D_REGULAR_ALPHA;
  hdma2d.LayerCfg[1].RedBlueSwap = DMA2D_RB_REGULAR;
  hdma2d.LayerCfg[1].ChromaSubSampling = DMA2D_NO_CSS;
  if (HAL_DMA2D_Init(&hdma2d) != HAL_OK)
  {
    Error_Handler();
  }
  if (HAL_DMA2D_ConfigLayer(&hdma2d, 1) != HAL_OK)
  {
    Error_Handler();
  }

}

static void MX_FDCAN1_Init(void)
{

  hfdcan1.Instance = FDCAN1;
  hfdcan1.Init.FrameFormat = FDCAN_FRAME_CLASSIC;
  hfdcan1.Init.Mode = FDCAN_MODE_NORMAL;
  hfdcan1.Init.AutoRetransmission = DISABLE;
  hfdcan1.Init.TransmitPause = DISABLE;
  hfdcan1.Init.ProtocolException = ENABLE;
  hfdcan1.Init.NominalPrescaler = 1;
  hfdcan1.Init.NominalSyncJumpWidth = 8;
  hfdcan1.Init.NominalTimeSeg1 = 31;
  hfdcan1.Init.NominalTimeSeg2 = 8;
  hfdcan1.Init.DataPrescaler = 1;
  hfdcan1.Init.DataSyncJumpWidth = 1;
  hfdcan1.Init.DataTimeSeg1 = 1;
  hfdcan1.Init.DataTimeSeg2 = 1;
  hfdcan1.Init.MessageRAMOffset = 0;
  hfdcan1.Init.StdFiltersNbr = 16;
  hfdcan1.Init.ExtFiltersNbr = 0;
  hfdcan1.Init.RxFifo0ElmtsNbr = 64;
  hfdcan1.Init.RxFifo0ElmtSize = FDCAN_DATA_BYTES_8;
  hfdcan1.Init.RxFifo1ElmtsNbr = 64;
  hfdcan1.Init.RxFifo1ElmtSize = FDCAN_DATA_BYTES_8;
  hfdcan1.Init.RxBuffersNbr = 0;
  hfdcan1.Init.RxBufferSize = FDCAN_DATA_BYTES_8;
  hfdcan1.Init.TxEventsNbr = 0;
  hfdcan1.Init.TxBuffersNbr = 0;
  hfdcan1.Init.TxFifoQueueElmtsNbr = 0;
  hfdcan1.Init.TxFifoQueueMode = FDCAN_TX_FIFO_OPERATION;
  hfdcan1.Init.TxElmtSize = FDCAN_DATA_BYTES_8;
  if (HAL_FDCAN_Init(&hfdcan1) != HAL_OK)
  {
    Error_Handler();
  }
  /* USER CODE BEGIN FDCAN1_Init 2 */
  /**
    * @brief  Configure the Rx FIFO operation mode.
    * @param  hfdcan pointer to an FDCAN_HandleTypeDef structure that contains
    *         the configuration information for the specified FDCAN.
    * @param  RxFifo Rx FIFO.
    *         This parameter can be one of the following values:
    *           @arg FDCAN_RX_FIFO0: Rx FIFO 0
    *           @arg FDCAN_RX_FIFO1: Rx FIFO 1
    * @param  OperationMode operation mode.
    *         This parameter can be a value of @arg FDCAN_Rx_FIFO_operation_mode.
    * @retval HAL status
    */
  HAL_FDCAN_ConfigRxFifoOverwrite(&hfdcan1,FDCAN_RX_FIFO0,FDCAN_RX_FIFO_OVERWRITE);

  HAL_FDCAN_ConfigRxFifoOverwrite(&hfdcan1,FDCAN_RX_FIFO1,FDCAN_RX_FIFO_OVERWRITE);

  /* Configure standard ID reception filter to Rx buffer 0 */
  sFilterConfig.IdType = FDCAN_STANDARD_ID;
  sFilterConfig.FilterIndex = 0;
  sFilterConfig.FilterType = FDCAN_FILTER_DUAL;
  sFilterConfig.FilterConfig = FDCAN_FILTER_TO_RXFIFO0;
  sFilterConfig.FilterID1 = CAN_ID_102;
  sFilterConfig.FilterID2 = CAN_ID_154;
  sFilterConfig.RxBufferIndex = 0;
  HAL_FDCAN_ConfigFilter(&hfdcan1, &sFilterConfig);

  sFilterConfig.IdType = FDCAN_STANDARD_ID;
  sFilterConfig.FilterIndex = 1;
  sFilterConfig.FilterType = FDCAN_FILTER_DUAL;
  sFilterConfig.FilterConfig = FDCAN_FILTER_TO_RXFIFO0;
  sFilterConfig.FilterID1 = CAN_ID_232;
  sFilterConfig.FilterID2 = CAN_ID_266;
  sFilterConfig.RxBufferIndex = 0;
  HAL_FDCAN_ConfigFilter(&hfdcan1, &sFilterConfig);

  /* Store RX in FIFO 1 from: ID 0x2AA to 0x6F2 */
  sFilterConfig.IdType = FDCAN_STANDARD_ID;
  sFilterConfig.FilterIndex = 7;
  sFilterConfig.FilterType = FDCAN_FILTER_DUAL;
  sFilterConfig.FilterConfig = FDCAN_FILTER_TO_RXFIFO1;
  sFilterConfig.FilterID1 = CAN_ID_382;
  sFilterConfig.FilterID2 = CAN_ID_3D2;
  sFilterConfig.RxBufferIndex = 0;
  HAL_FDCAN_ConfigFilter(&hfdcan1, &sFilterConfig);

  sFilterConfig.IdType = FDCAN_STANDARD_ID;
  sFilterConfig.FilterIndex = 8;
  sFilterConfig.FilterType = FDCAN_FILTER_DUAL;
  sFilterConfig.FilterConfig = FDCAN_FILTER_TO_RXFIFO1;
  sFilterConfig.FilterID1 = CAN_ID_562;
  sFilterConfig.FilterID2 = CAN_ID_562;
  sFilterConfig.RxBufferIndex = 0;
  HAL_FDCAN_ConfigFilter(&hfdcan1, &sFilterConfig);

HAL_FDCAN_ConfigGlobalFilter(&hfdcan1,
		  FDCAN_REJECT,
		  FDCAN_REJECT,
		  FDCAN_REJECT_REMOTE,
		  FDCAN_REJECT_REMOTE);

  /* USER CODE END FDCAN1_Init 2 */

}

static void MX_I2C4_Init(void)
{

  hi2c4.Instance = I2C4;
  hi2c4.Init.Timing = 0x307075B1;
  hi2c4.Init.OwnAddress1 = 0;
  hi2c4.Init.AddressingMode = I2C_ADDRESSINGMODE_7BIT;
  hi2c4.Init.DualAddressMode = I2C_DUALADDRESS_DISABLE;
  hi2c4.Init.OwnAddress2 = 0;
  hi2c4.Init.OwnAddress2Masks = I2C_OA2_NOMASK;
  hi2c4.Init.GeneralCallMode = I2C_GENERALCALL_DISABLE;
  hi2c4.Init.NoStretchMode = I2C_NOSTRETCH_DISABLE;
  if (HAL_I2C_Init(&hi2c4) != HAL_OK)
  {
    Error_Handler();
  }
  /** Configure Analogue filter
  */
  if (HAL_I2CEx_ConfigAnalogFilter(&hi2c4, I2C_ANALOGFILTER_ENABLE) != HAL_OK)
  {
    Error_Handler();
  }
  /** Configure Digital filter
  */
  if (HAL_I2CEx_ConfigDigitalFilter(&hi2c4, 0) != HAL_OK)
  {
    Error_Handler();
  }

}

static void MX_I2S6_Init(void)
{

  /* USER CODE BEGIN I2S6_Init 0 */
//hi2s6.Init.Mode = I2S_MODE_MASTER_FULLDUPLEX;------------------------
  /* USER CODE END I2S6_Init 0 */

  hi2s6.Instance = SPI6;
  hi2s6.Init.Mode = I2S_MODE_MASTER_TX;
  hi2s6.Init.Standard = I2S_STANDARD_PHILIPS;
  hi2s6.Init.DataFormat = I2S_DATAFORMAT_16B;
  hi2s6.Init.MCLKOutput = I2S_MCLKOUTPUT_ENABLE;
  hi2s6.Init.AudioFreq = I2S_AUDIOFREQ_8K;
  hi2s6.Init.CPOL = I2S_CPOL_LOW;
  hi2s6.Init.FirstBit = I2S_FIRSTBIT_MSB;
  hi2s6.Init.WSInversion = I2S_WS_INVERSION_DISABLE;
  hi2s6.Init.Data24BitAlignment = I2S_DATA_24BIT_ALIGNMENT_RIGHT;
  hi2s6.Init.MasterKeepIOState = I2S_MASTER_KEEP_IO_STATE_DISABLE;
  if (HAL_I2S_Init(&hi2s6) != HAL_OK)
  {
    Error_Handler();
  }

}

static void MX_LTDC_Init(void)
{

  LTDC_LayerCfgTypeDef pLayerCfg = {0};

  hltdc.Instance = LTDC;
  hltdc.Init.HSPolarity = LTDC_HSPOLARITY_AL;
  hltdc.Init.VSPolarity = LTDC_VSPOLARITY_AL;
  hltdc.Init.DEPolarity = LTDC_DEPOLARITY_AL;
  hltdc.Init.PCPolarity = LTDC_PCPOLARITY_IPC;
  hltdc.Init.HorizontalSync = 40;
  hltdc.Init.VerticalSync = 9;
  hltdc.Init.AccumulatedHBP = 42;
  hltdc.Init.AccumulatedVBP = 11;
  hltdc.Init.AccumulatedActiveW = 522;
  hltdc.Init.AccumulatedActiveH = 283;
  hltdc.Init.TotalWidth = 554;
  hltdc.Init.TotalHeigh = 285;
  hltdc.Init.Backcolor.Blue = 0;
  hltdc.Init.Backcolor.Green = 0;
  hltdc.Init.Backcolor.Red = 0;
  if (HAL_LTDC_Init(&hltdc) != HAL_OK)
  {
    Error_Handler();
  }
  pLayerCfg.WindowX0 = 0;
  pLayerCfg.WindowX1 = 480;
  pLayerCfg.WindowY0 = 0;
  pLayerCfg.WindowY1 = 272;
  pLayerCfg.PixelFormat = LTDC_PIXEL_FORMAT_RGB888;
  pLayerCfg.Alpha = 255;
  pLayerCfg.Alpha0 = 0;
  pLayerCfg.BlendingFactor1 = LTDC_BLENDING_FACTOR1_CA;
  pLayerCfg.BlendingFactor2 = LTDC_BLENDING_FACTOR2_CA;
  pLayerCfg.FBStartAdress = 0xD0000000;
  pLayerCfg.ImageWidth = 480;
  pLayerCfg.ImageHeight = 272;
  pLayerCfg.Backcolor.Blue = 255;
  pLayerCfg.Backcolor.Green = 0;
  pLayerCfg.Backcolor.Red = 0;
  if (HAL_LTDC_ConfigLayer(&hltdc, &pLayerCfg, 0) != HAL_OK)
  {
    Error_Handler();
  }
  /* USER CODE BEGIN LTDC_Init 2 */
//  HAL_LTDC_SetAddress(&hltdc, framebuffer, LTDC_LAYER_1);

  /* USER CODE END LTDC_Init 2 */

}

static void MX_OCTOSPI1_Init(void)
{

  /* USER CODE BEGIN OCTOSPI1_Init 0 */
#if 0
	typedef enum {
	  MX25LM51245G_STR_TRANSFER = 0,             /*!< Single Transfer Rate                          */
	  MX25LM51245G_DTR_TRANSFER                  /*!< Double Transfer Rate                          */
	} MX25LM51245G_Transfer_t;
	typedef enum {
	  MX25LM51245G_SPI_MODE = 0,                 /*!< 1-1-1 commands, Power on H/W default setting  */
	  MX25LM51245G_OPI_MODE                      /*!< 8-8-8 commands                                */
	} MX25LM51245G_Interface_t;
	typedef struct
	{
	  BSP_OSPI_NOR_Interface_t   InterfaceMode;      /*!<  Current Flash Interface mode */
	  BSP_OSPI_NOR_Transfer_t    TransferRate;       /*!<  Current Flash Transfer rate  */
	} BSP_OSPI_NOR_Init_t;

	uint32_t Instance = 1;
	BSP_OSPI_NOR_Init_t Init;
	Init.InterfaceMode = MX25LM51245G_OPI_MODE;
	Init.TransferRate = MX25LM51245G_DTR_TRANSFER;
	int32_t sta =  BSP_OSPI_NOR_Init(Instance, &Init);
//	Printf("Status of BSP_OSPI_NOR_Init(Instance, &Init) %i", sta);
#endif
  /* USER CODE END OCTOSPI1_Init 0 */
#if 1
//  OSPIM_CfgTypeDef sOspiManagerCfg = {0};
  OSPI_MemoryMappedTypeDef sMemMappedCfg = {0};

  /* USER CODE BEGIN OCTOSPI1_Init 1 */
  HAL_OSPI_DeInit(&hospi1);
  /* USER CODE END OCTOSPI1_Init 1 */
  /* OCTOSPI1 parameter configuration*/
  hospi1.Instance = OCTOSPI1;
  hospi1.Init.FifoThreshold = 1;
  hospi1.Init.DualQuad = HAL_OSPI_DUALQUAD_DISABLE;
  hospi1.Init.MemoryType = HAL_OSPI_MEMTYPE_MICRON;
  hospi1.Init.DeviceSize = 26;
  hospi1.Init.ChipSelectHighTime = 2;
  hospi1.Init.FreeRunningClock = HAL_OSPI_FREERUNCLK_DISABLE;
  hospi1.Init.ClockMode = HAL_OSPI_CLOCK_MODE_0;
  hospi1.Init.WrapSize = HAL_OSPI_WRAP_NOT_SUPPORTED;
  hospi1.Init.ClockPrescaler = 3;
  hospi1.Init.SampleShifting = HAL_OSPI_SAMPLE_SHIFTING_NONE;
  hospi1.Init.DelayHoldQuarterCycle = HAL_OSPI_DHQC_ENABLE;
  hospi1.Init.ChipSelectBoundary = 0;
  hospi1.Init.ClkChipSelectHighTime = 0;
  hospi1.Init.DelayBlockBypass = HAL_OSPI_DELAY_BLOCK_BYPASSED;
  hospi1.Init.MaxTran = 0;
  hospi1.Init.Refresh = 0;
  if (HAL_OSPI_Init(&hospi1) != HAL_OK)
  {
    Error_Handler();
  }
//  sOspiManagerCfg.ClkPort = 1;
//  sOspiManagerCfg.DQSPort = 1;
//  sOspiManagerCfg.NCSPort = 1;
//  sOspiManagerCfg.IOLowPort = HAL_OSPIM_IOPORT_1_LOW;
//  sOspiManagerCfg.IOHighPort = HAL_OSPIM_IOPORT_1_HIGH;
//
//  if (HAL_OSPIM_Config(&hospi1, &sOspiManagerCfg, HAL_OSPI_TIMEOUT_DEFAULT_VALUE) != HAL_OK)
//  {
//    Error_Handler();
//  }
  sMemMappedCfg.TimeOutActivation = HAL_OSPI_TIMEOUT_COUNTER_DISABLE;
  sMemMappedCfg.TimeOutPeriod = 1;

  if (HAL_OSPI_MemoryMapped(&hospi1, &sMemMappedCfg) != HAL_OK)
  {
    Error_Handler();
  }
#endif
  /* USER CODE BEGIN OCTOSPI1_Init 2 */
  BSP_OSPI_NOR_Init_t Flash;
  Flash.InterfaceMode = BSP_OSPI_NOR_OPI_MODE;
  Flash.TransferRate  = BSP_OSPI_NOR_DTR_TRANSFER;
  BSP_OSPI_NOR_DeInit(0);
  int32_t RetVal = BSP_OSPI_NOR_Init(0, &Flash);
  if(RetVal != BSP_ERROR_NONE)
  {
    Error_Handler();
  }
  RetVal = BSP_OSPI_NOR_EnableMemoryMappedMode(0);
  if(RetVal != BSP_ERROR_NONE)
  {
    Error_Handler();
  }
  /* USER CODE END OCTOSPI1_Init 2 */

}

static void MX_RTC_Init(void)
{

  /** Initialize RTC Only
  */
  hrtc.Instance = RTC;
  hrtc.Init.HourFormat = RTC_HOURFORMAT_24;
  hrtc.Init.AsynchPrediv = 127;
  hrtc.Init.SynchPrediv = 255;
  hrtc.Init.OutPut = RTC_OUTPUT_DISABLE;
  hrtc.Init.OutPutPolarity = RTC_OUTPUT_POLARITY_HIGH;
  hrtc.Init.OutPutType = RTC_OUTPUT_TYPE_OPENDRAIN;
  hrtc.Init.OutPutRemap = RTC_OUTPUT_REMAP_NONE;
  if (HAL_RTC_Init(&hrtc) != HAL_OK)
  {
    Error_Handler();
  }
  /* USER CODE BEGIN RTC_Init 2 */
  RTC_DateTypeDef sdatestructure;
  RTC_TimeTypeDef stimestructure;
//  uint32_t Format;
  /*##-2- Configure the Date #################################################*/
  /* Set Date: Monday February 01 2016 */
  sdatestructure.Year    = 0x16;
  sdatestructure.Month   = RTC_MONTH_FEBRUARY;
  sdatestructure.Date    = 0x01;
  sdatestructure.WeekDay = RTC_WEEKDAY_MONDAY;

  if (HAL_RTC_SetDate(&hrtc, &sdatestructure, RTC_FORMAT_BCD) != HAL_OK)
  {
    /* Initialization Error */
    Error_Handler();
  }
  /*##-3- Configure the Time #################################################*/
  /* Set Time: 08:10:00 */
  stimestructure.Hours          = 0x08;
  stimestructure.Minutes        = 0x10;
  stimestructure.Seconds        = 0x00;
  stimestructure.SubSeconds     = 0x00;
  stimestructure.TimeFormat     = RTC_HOURFORMAT12_AM;
  stimestructure.DayLightSaving = RTC_DAYLIGHTSAVING_NONE ;
  stimestructure.StoreOperation = RTC_STOREOPERATION_RESET;

  if (HAL_RTC_SetTime(&hrtc, &stimestructure, RTC_FORMAT_BCD) != HAL_OK)
  {
    /* Initialization Error */
    Error_Handler();
  }

  /* USER CODE END RTC_Init 2 */

}

static void MX_SDMMC1_SD_Init(void)
{

  hsd1.Instance = SDMMC1;
  hsd1.Init.ClockEdge = SDMMC_CLOCK_EDGE_RISING;
  hsd1.Init.ClockPowerSave = SDMMC_CLOCK_POWER_SAVE_DISABLE;
  hsd1.Init.BusWide = SDMMC_BUS_WIDE_4B;
  hsd1.Init.HardwareFlowControl = SDMMC_HARDWARE_FLOW_CONTROL_DISABLE;
  hsd1.Init.ClockDiv = 0;
  hsd1.Init.TranceiverPresent = SDMMC_TRANSCEIVER_NOT_PRESENT;
  if (HAL_SD_Init(&hsd1) != HAL_OK)
  {
    Error_Handler();
  }

}

static void MX_USART1_UART_Init(void)
{

  huart1.Instance = USART1;
  huart1.Init.BaudRate = 115200;
  huart1.Init.WordLength = UART_WORDLENGTH_8B;
  huart1.Init.StopBits = UART_STOPBITS_1;
  huart1.Init.Parity = UART_PARITY_NONE;
  huart1.Init.Mode = UART_MODE_TX_RX;
  huart1.Init.HwFlowCtl = UART_HWCONTROL_NONE;
  huart1.Init.OverSampling = UART_OVERSAMPLING_16;
  huart1.Init.OneBitSampling = UART_ONE_BIT_SAMPLE_DISABLE;
  huart1.Init.ClockPrescaler = UART_PRESCALER_DIV1;
  huart1.AdvancedInit.AdvFeatureInit = UART_ADVFEATURE_NO_INIT;
  if (HAL_UART_Init(&huart1) != HAL_OK)
  {
    Error_Handler();
  }
//  if (HAL_UARTEx_SetTxFifoThreshold(&huart1, UART_TXFIFO_THRESHOLD_1_8) != HAL_OK)
//  {
//    Error_Handler();
//  }
//  if (HAL_UARTEx_SetRxFifoThreshold(&huart1, UART_RXFIFO_THRESHOLD_1_8) != HAL_OK)
//  {
//    Error_Handler();
//  }
//  if (HAL_UARTEx_DisableFifoMode(&huart1) != HAL_OK)
//  {
//    Error_Handler();
//  }

}

static void MX_DMA_Init(void)
{

  /* DMA controller clock enable */
  __HAL_RCC_DMA1_CLK_ENABLE();

  /* DMA interrupt init */
  /* DMA1_Stream0_IRQn interrupt configuration */
  HAL_NVIC_SetPriority(DMA1_Stream0_IRQn, 5, 0);
  HAL_NVIC_EnableIRQ(DMA1_Stream0_IRQn);

}

static void MX_GPIO_Init(void)
{
  GPIO_InitTypeDef GPIO_InitStruct = {0};

  /* GPIO Ports Clock Enable */
  __HAL_RCC_GPIOG_CLK_ENABLE();
  __HAL_RCC_GPIOK_CLK_ENABLE();
  __HAL_RCC_GPIOD_CLK_ENABLE();
  __HAL_RCC_GPIOC_CLK_ENABLE();
  __HAL_RCC_GPIOE_CLK_ENABLE();
  __HAL_RCC_GPIOJ_CLK_ENABLE();
  __HAL_RCC_GPIOA_CLK_ENABLE();
  __HAL_RCC_GPIOI_CLK_ENABLE();
  __HAL_RCC_GPIOF_CLK_ENABLE();
  __HAL_RCC_GPIOH_CLK_ENABLE();
  __HAL_RCC_GPIOB_CLK_ENABLE();

  /*Configure GPIO pin Output Level */
  HAL_GPIO_WritePin(GPIOG, LED3_Pin|LED2_Pin, GPIO_PIN_RESET);

  /*Configure GPIO pin Output Level */
  HAL_GPIO_WritePin(GPIOA, VSYNC_FREQ_Pin|LCD_BL_CTRL_Pin|LCD_ON_OFF_Pin, GPIO_PIN_RESET);

  /*Configure GPIO pin Output Level */
  HAL_GPIO_WritePin(MCU_ACTIVE_GPIO_Port, MCU_ACTIVE_Pin, GPIO_PIN_RESET);

  /*Configure GPIO pin Output Level */
  HAL_GPIO_WritePin(GPIOB, RENDER_TIME_Pin|FRAME_RATE_Pin, GPIO_PIN_RESET);

  /*Configure GPIO pin Output Level */
  HAL_GPIO_WritePin(FDCAN1_STDBY_GPIO_Port, FDCAN1_STDBY_Pin, GPIO_PIN_RESET);

  /*Configure GPIO pins : LED3_Pin LED2_Pin */
  GPIO_InitStruct.Pin = LED3_Pin|LED2_Pin;
  GPIO_InitStruct.Mode = GPIO_MODE_OUTPUT_PP;
  GPIO_InitStruct.Pull = GPIO_NOPULL;
  GPIO_InitStruct.Speed = GPIO_SPEED_FREQ_LOW;
  HAL_GPIO_Init(GPIOG, &GPIO_InitStruct);

  /*Configure GPIO pins : VSYNC_FREQ_Pin LCD_BL_CTRL_Pin */
  GPIO_InitStruct.Pin = VSYNC_FREQ_Pin|LCD_BL_CTRL_Pin;
  GPIO_InitStruct.Mode = GPIO_MODE_OUTPUT_PP;
  GPIO_InitStruct.Pull = GPIO_NOPULL;
  GPIO_InitStruct.Speed = GPIO_SPEED_FREQ_LOW;
  HAL_GPIO_Init(GPIOA, &GPIO_InitStruct);

  /*Configure GPIO pin : MCU_ACTIVE_Pin */
  GPIO_InitStruct.Pin = MCU_ACTIVE_Pin;
  GPIO_InitStruct.Mode = GPIO_MODE_OUTPUT_PP;
  GPIO_InitStruct.Pull = GPIO_NOPULL;
  GPIO_InitStruct.Speed = GPIO_SPEED_FREQ_LOW;
  HAL_GPIO_Init(MCU_ACTIVE_GPIO_Port, &GPIO_InitStruct);

  /*Configure GPIO pin : RCC_MCO_Pin */
  GPIO_InitStruct.Pin = RCC_MCO_Pin;
  GPIO_InitStruct.Mode = GPIO_MODE_AF_PP;
  GPIO_InitStruct.Pull = GPIO_NOPULL;
  GPIO_InitStruct.Speed = GPIO_SPEED_FREQ_LOW;
  GPIO_InitStruct.Alternate = GPIO_AF0_MCO;
  HAL_GPIO_Init(RCC_MCO_GPIO_Port, &GPIO_InitStruct);

  /*Configure GPIO pin : LCD_INT_Pin */
  GPIO_InitStruct.Pin = LCD_INT_Pin;
  GPIO_InitStruct.Mode = GPIO_MODE_IT_RISING;
  GPIO_InitStruct.Pull = GPIO_PULLUP;
  HAL_GPIO_Init(LCD_INT_GPIO_Port, &GPIO_InitStruct);

  /*Configure GPIO pins : RENDER_TIME_Pin FRAME_RATE_Pin */
  GPIO_InitStruct.Pin = RENDER_TIME_Pin|FRAME_RATE_Pin;
  GPIO_InitStruct.Mode = GPIO_MODE_OUTPUT_PP;
  GPIO_InitStruct.Pull = GPIO_NOPULL;
  GPIO_InitStruct.Speed = GPIO_SPEED_FREQ_LOW;
  HAL_GPIO_Init(GPIOB, &GPIO_InitStruct);

  /*Configure GPIO pin : FDCAN1_STDBY_Pin */
  GPIO_InitStruct.Pin = FDCAN1_STDBY_Pin;
  GPIO_InitStruct.Mode = GPIO_MODE_OUTPUT_PP;
  GPIO_InitStruct.Pull = GPIO_NOPULL;
  GPIO_InitStruct.Speed = GPIO_SPEED_FREQ_LOW;
  HAL_GPIO_Init(FDCAN1_STDBY_GPIO_Port, &GPIO_InitStruct);

  /*Configure GPIO pin : LCD_ON_OFF_Pin */
  GPIO_InitStruct.Pin = LCD_ON_OFF_Pin;
  GPIO_InitStruct.Mode = GPIO_MODE_OUTPUT_PP;
  GPIO_InitStruct.Pull = GPIO_PULLUP;
  GPIO_InitStruct.Speed = GPIO_SPEED_FREQ_LOW;
  HAL_GPIO_Init(LCD_ON_OFF_GPIO_Port, &GPIO_InitStruct);

  /* EXTI interrupt init*/
  HAL_NVIC_SetPriority(EXTI2_IRQn, 5, 0);
  HAL_NVIC_EnableIRQ(EXTI2_IRQn);

}

/* USER CODE BEGIN 4 */

void Printf(const char *fmt, ...)
{
			#define BUFFER_SIZE 100
	  	  	uint8_t Buff[BUFFER_SIZE];
 			va_list args;
			va_start(args, fmt);
			vsnprintf((char *)Buff, BUFFER_SIZE, fmt, args);
			va_end(args);
			HAL_UART_Transmit(&huart1, Buff,(uint16_t) strlen((char *)Buff),(uint32_t) 10);

}

/* USER CODE END 4 */

/* MPU Configuration */

void MPU_Config(void)
{
  MPU_Region_InitTypeDef MPU_InitStruct = {0};

  /* Disables the MPU */
  HAL_MPU_Disable();
  /** Initializes and configures the Region and the memory to be protected
  */
  MPU_InitStruct.Enable = MPU_REGION_ENABLE;
  MPU_InitStruct.Number = MPU_REGION_NUMBER0;
  MPU_InitStruct.BaseAddress = 0x90000000;
  MPU_InitStruct.Size = MPU_REGION_SIZE_256MB;
  MPU_InitStruct.SubRegionDisable = 0x0;
  MPU_InitStruct.TypeExtField = MPU_TEX_LEVEL0;
  MPU_InitStruct.AccessPermission = MPU_REGION_NO_ACCESS;
  MPU_InitStruct.DisableExec = MPU_INSTRUCTION_ACCESS_DISABLE;
  MPU_InitStruct.IsShareable = MPU_ACCESS_NOT_SHAREABLE;
  MPU_InitStruct.IsCacheable = MPU_ACCESS_NOT_CACHEABLE;
  MPU_InitStruct.IsBufferable = MPU_ACCESS_NOT_BUFFERABLE;

  HAL_MPU_ConfigRegion(&MPU_InitStruct);
  /** Initializes and configures the Region and the memory to be protected
  */
  MPU_InitStruct.Enable = MPU_REGION_ENABLE;
  MPU_InitStruct.Number = MPU_REGION_NUMBER1;
  MPU_InitStruct.BaseAddress = 0x90000000;
  MPU_InitStruct.Size = MPU_REGION_SIZE_64MB;
  MPU_InitStruct.SubRegionDisable = 0x0;
  MPU_InitStruct.TypeExtField = MPU_TEX_LEVEL0;
  MPU_InitStruct.AccessPermission = MPU_REGION_FULL_ACCESS;
  MPU_InitStruct.DisableExec = MPU_INSTRUCTION_ACCESS_DISABLE;
  MPU_InitStruct.IsShareable = MPU_ACCESS_NOT_SHAREABLE;
  MPU_InitStruct.IsCacheable = MPU_ACCESS_CACHEABLE;
  MPU_InitStruct.IsBufferable = MPU_ACCESS_NOT_BUFFERABLE;

  HAL_MPU_ConfigRegion(&MPU_InitStruct);
  /** Initializes and configures the Region and the memory to be protected
  */
  MPU_InitStruct.Enable = MPU_REGION_ENABLE;
  MPU_InitStruct.Number = MPU_REGION_NUMBER2;
  MPU_InitStruct.BaseAddress = 0x24000000;
  MPU_InitStruct.Size = MPU_REGION_SIZE_1MB;
  MPU_InitStruct.SubRegionDisable = 0x0;
  MPU_InitStruct.TypeExtField = MPU_TEX_LEVEL0;
  MPU_InitStruct.AccessPermission = MPU_REGION_FULL_ACCESS;
  MPU_InitStruct.DisableExec = MPU_INSTRUCTION_ACCESS_DISABLE;
  MPU_InitStruct.IsShareable = MPU_ACCESS_NOT_SHAREABLE;
  MPU_InitStruct.IsCacheable = MPU_ACCESS_CACHEABLE;
  MPU_InitStruct.IsBufferable = MPU_ACCESS_NOT_BUFFERABLE;

  HAL_MPU_ConfigRegion(&MPU_InitStruct);
  /** Initializes and configures the Region and the memory to be protected
  */
  MPU_InitStruct.Enable = MPU_REGION_ENABLE;
  MPU_InitStruct.Number = MPU_REGION_NUMBER3;
  MPU_InitStruct.BaseAddress = 0x24000000;
  MPU_InitStruct.Size = MPU_REGION_SIZE_256KB;
  MPU_InitStruct.SubRegionDisable = 0x0;
  MPU_InitStruct.TypeExtField = MPU_TEX_LEVEL0;
  MPU_InitStruct.AccessPermission = MPU_REGION_FULL_ACCESS;
  MPU_InitStruct.DisableExec = MPU_INSTRUCTION_ACCESS_DISABLE;
  MPU_InitStruct.IsShareable = MPU_ACCESS_NOT_SHAREABLE;
  MPU_InitStruct.IsCacheable = MPU_ACCESS_CACHEABLE;
  MPU_InitStruct.IsBufferable = MPU_ACCESS_BUFFERABLE;

  HAL_MPU_ConfigRegion(&MPU_InitStruct);
  /* Enables the MPU */
  HAL_MPU_Enable(MPU_PRIVILEGED_DEFAULT);

}
void HAL_TIM_PeriodElapsedCallback(TIM_HandleTypeDef *htim)
{
  if (htim->Instance == TIM7) {
    HAL_IncTick();
  }
  else if(htim->Instance == TIM2){
	  time_seconds++;
  }
}

void Error_Handler(void)
{
}

/************************ (C) COPYRIGHT STMicroelectronics *****END OF FILE****/

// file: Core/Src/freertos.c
/* USER CODE BEGIN Header */
/**
  ******************************************************************************
  * File Name          : freertos.c
  * Description        : Code for freertos applications
  ******************************************************************************
  * @attention
  *
  * <h2><center>&copy; Copyright (c) 2020 STMicroelectronics.
  * All rights reserved.</center></h2>
  *
  * This software component is licensed by ST under Ultimate Liberty license
  * SLA0044, the "License"; You may not use this file except in compliance with
  * the License. You may obtain a copy of the License at:
  *                             www.st.com/SLA0044
  *
  ******************************************************************************
  */
/* USER CODE END Header */

#include "FreeRTOS.h"
#include "task.h"
#include "main.h"

/* GetIdleTaskMemory prototype (linked to static allocation support) */
void vApplicationGetIdleTaskMemory( StaticTask_t **ppxIdleTaskTCBBuffer, StackType_t **ppxIdleTaskStackBuffer, uint32_t *pulIdleTaskStackSize );

/* Hook prototypes */
void configureTimerForRunTimeStats(void);
unsigned long getRunTimeCounterValue(void);
void vApplicationStackOverflowHook(xTaskHandle xTask, signed char *pcTaskName);

/* USER CODE BEGIN 1 */
/* Functions needed when configGENERATE_RUN_TIME_STATS is on */
__weak void configureTimerForRunTimeStats(void)
{

}

__weak unsigned long getRunTimeCounterValue(void)
{
return 0;
}
/* USER CODE END 1 */

/* USER CODE BEGIN 4 */
__weak void vApplicationStackOverflowHook(xTaskHandle xTask, signed char *pcTaskName)
{
   /* Run time stack overflow checking is performed if
   configCHECK_FOR_STACK_OVERFLOW is defined to 1 or 2. This hook function is
   called if a stack overflow is detected. */
}
/* USER CODE END 4 */

/* USER CODE BEGIN GET_IDLE_TASK_MEMORY */
static StaticTask_t xIdleTaskTCBBuffer;
static StackType_t xIdleStack[configMINIMAL_STACK_SIZE];

void vApplicationGetIdleTaskMemory( StaticTask_t **ppxIdleTaskTCBBuffer, StackType_t **ppxIdleTaskStackBuffer, uint32_t *pulIdleTaskStackSize )
{
  *ppxIdleTaskTCBBuffer = &xIdleTaskTCBBuffer;
  *ppxIdleTaskStackBuffer = &xIdleStack[0];
  *pulIdleTaskStackSize = configMINIMAL_STACK_SIZE;
  /* place for user code */
}
/* USER CODE END GET_IDLE_TASK_MEMORY */

/************************ (C) COPYRIGHT STMicroelectronics *****END OF FILE****/
